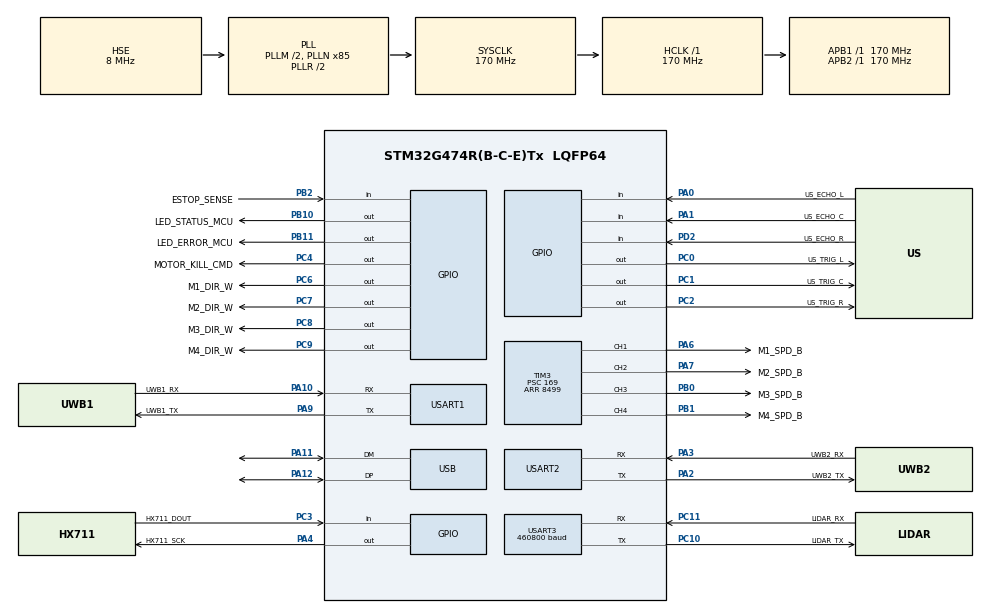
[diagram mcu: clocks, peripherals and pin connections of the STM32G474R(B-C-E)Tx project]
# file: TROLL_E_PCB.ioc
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Dma.Request0=USART3_RX
Dma.Request1=USART1_RX
Dma.Request2=USART2_RX
Dma.USART1_RX.1.Direction=DMA_PERIPH_TO_MEMORY
Dma.USART1_RX.1.EventEnable=DISABLE
Dma.USART1_RX.1.Instance=DMA1_Channel2
Dma.USART1_RX.1.MemDataAlignment=DMA_MDATAALIGN_BYTE
Dma.USART1_RX.1.MemInc=DMA_MINC_ENABLE
Dma.USART1_RX.1.Mode=DMA_CIRCULAR
Dma.USART1_RX.1.PeriphDataAlignment=DMA_PDATAALIGN_BYTE
Dma.USART1_RX.1.PeriphInc=DMA_PINC_DISABLE
Dma.USART1_RX.1.Polarity=HAL_DMAMUX_REQ_GEN_RISING
Dma.USART1_RX.1.Priority=DMA_PRIORITY_LOW
Dma.USART1_RX.1.RequestNumber=1
Dma.USART1_RX.1.SignalID=NONE
Dma.USART1_RX.1.SyncEnable=DISABLE
Dma.USART1_RX.1.SyncPolarity=HAL_DMAMUX_SYNC_NO_EVENT
Dma.USART1_RX.1.SyncRequestNumber=1
Dma.USART1_RX.1.SyncSignalID=NONE
Dma.USART2_RX.2.Direction=DMA_PERIPH_TO_MEMORY
Dma.USART2_RX.2.EventEnable=DISABLE
Dma.USART2_RX.2.Instance=DMA1_Channel3
Dma.USART2_RX.2.MemDataAlignment=DMA_MDATAALIGN_BYTE
Dma.USART2_RX.2.MemInc=DMA_MINC_ENABLE
Dma.USART2_RX.2.Mode=DMA_CIRCULAR
Dma.USART2_RX.2.PeriphDataAlignment=DMA_PDATAALIGN_BYTE
Dma.USART2_RX.2.PeriphInc=DMA_PINC_DISABLE
Dma.USART2_RX.2.Polarity=HAL_DMAMUX_REQ_GEN_RISING
Dma.USART2_RX.2.Priority=DMA_PRIORITY_LOW
Dma.USART2_RX.2.RequestNumber=1
Dma.USART2_RX.2.SignalID=NONE
Dma.USART2_RX.2.SyncEnable=DISABLE
Dma.USART2_RX.2.SyncPolarity=HAL_DMAMUX_SYNC_NO_EVENT
Dma.USART2_RX.2.SyncRequestNumber=1
Dma.USART2_RX.2.SyncSignalID=NONE
Dma.USART3_RX.0.Direction=DMA_PERIPH_TO_MEMORY
Dma.USART3_RX.0.EventEnable=DISABLE
Dma.USART3_RX.0.Instance=DMA1_Channel1
Dma.USART3_RX.0.MemDataAlignment=DMA_MDATAALIGN_BYTE
Dma.USART3_RX.0.MemInc=DMA_MINC_ENABLE
Dma.USART3_RX.0.Mode=DMA_CIRCULAR
Dma.USART3_RX.0.PeriphDataAlignment=DMA_PDATAALIGN_BYTE
Dma.USART3_RX.0.PeriphInc=DMA_PINC_DISABLE
Dma.USART3_RX.0.Polarity=HAL_DMAMUX_REQ_GEN_RISING
Dma.USART3_RX.0.Priority=DMA_PRIORITY_LOW
Dma.USART3_RX.0.RequestNumber=1
Dma.USART3_RX.0.SignalID=NONE
Dma.USART3_RX.0.SyncEnable=DISABLE
Dma.USART3_RX.0.SyncPolarity=HAL_DMAMUX_SYNC_NO_EVENT
Dma.USART3_RX.0.SyncRequestNumber=1
Dma.USART3_RX.0.SyncSignalID=NONE
Mcu.Family=STM32G4
Mcu.Name=STM32G474R(B-C-E)Tx
Mcu.Package=LQFP64
NVIC.DMA1_Channel1_IRQn=true\:0\:0\:false\:false\:true\:false\:true\:true
NVIC.DMA1_Channel2_IRQn=true\:0\:0\:false\:false\:true\:false\:true\:true
NVIC.DMA1_Channel3_IRQn=true\:0\:0\:false\:false\:true\:false\:true\:true
NVIC.PriorityGroup=NVIC_PRIORITYGROUP_4
NVIC.USART1_IRQn=true\:0\:0\:false\:false\:true\:true\:true\:true
NVIC.USART2_IRQn=true\:0\:0\:false\:false\:true\:true\:true\:true
NVIC.USART3_IRQn=true\:0\:0\:false\:false\:true\:true\:true\:true
NVIC.USB_LP_IRQn=true\:0\:0\:false\:false\:true\:false\:true\:true
PA0.GPIO_Label=US_ECHO_L
PA0.Signal=GPIO_Input
PA1.GPIO_Label=US_ECHO_C
PA1.Signal=GPIO_Input
PA10.GPIO_Label=UWB1_RX
PA10.Mode=Asynchronous
PA10.Signal=USART1_RX
PA11.Mode=Device
PA11.Signal=USB_DM
PA12.Mode=Device
PA12.Signal=USB_DP
PA13.Mode=Serial_Wire
PA13.Signal=SYS_JTMS-SWDIO
PA14.Mode=Serial_Wire
PA14.Signal=SYS_JTCK-SWCLK
PA2.GPIO_Label=UWB2_TX
PA2.Mode=Asynchronous
PA2.Signal=USART2_TX
PA3.GPIO_Label=UWB2_RX
PA3.Mode=Asynchronous
PA3.Signal=USART2_RX
PA4.GPIO_Label=HX711_SCK
PA4.GPIO_PuPd=GPIO_NOPULL
PA4.Signal=GPIO_Output
PA6.GPIO_Label=M1_SPD_B
PA6.Signal=S_TIM3_CH1
PA7.GPIO_Label=M2_SPD_B
PA7.Signal=S_TIM3_CH2
PA9.GPIO_Label=UWB1_TX
PA9.Mode=Asynchronous
PA9.Signal=USART1_TX
PB0.GPIO_Label=M3_SPD_B
PB0.Signal=S_TIM3_CH3
PB1.GPIO_Label=M4_SPD_B
PB1.Signal=S_TIM3_CH4
PB10.GPIO_Label=LED_STATUS_MCU
PB10.Signal=GPIO_Output
PB11.GPIO_Label=LED_ERROR_MCU
PB11.Signal=GPIO_Output
PB2.GPIO_Label=ESTOP_SENSE
PB2.Signal=GPIO_Input
PC0.GPIO_Label=US_TRIG_L
PC0.Signal=GPIO_Output
PC1.GPIO_Label=US_TRIG_C
PC1.Signal=GPIO_Output
PC10.GPIO_Label=LiDAR_TX
PC10.Mode=Asynchronous
PC10.Signal=USART3_TX
PC11.GPIO_Label=LiDAR_RX
PC11.Mode=Asynchronous
PC11.Signal=USART3_RX
PC2.GPIO_Label=US_TRIG_R
PC2.Signal=GPIO_Output
PC3.GPIO_Label=HX711_DOUT
PC3.GPIO_PuPd=GPIO_PULLUP
PC3.Signal=GPIO_Input
PC4.GPIO_Label=MOTOR_KILL_CMD
PC4.PinState=GPIO_PIN_SET
PC4.Signal=GPIO_Output
PC6.GPIO_Label=M1_DIR_W
PC6.Signal=GPIO_Output
PC7.GPIO_Label=M2_DIR_W
PC7.Signal=GPIO_Output
PC8.GPIO_Label=M3_DIR_W
PC8.Signal=GPIO_Output
PC9.GPIO_Label=M4_DIR_W
PC9.Signal=GPIO_Output
PD2.GPIO_Label=US_ECHO_R
PD2.Signal=GPIO_Input
PF0-OSC_IN.Mode=HSE-External-Oscillator
PF0-OSC_IN.Signal=RCC_OSC_IN
PF1-OSC_OUT.Mode=HSE-External-Oscillator
PF1-OSC_OUT.Signal=RCC_OSC_OUT
ProjectManager.HeapSize=0x1000
ProjectManager.StackSize=0x400
ProjectManager.TargetToolchain=STM32CubeIDE
RCC.ADC12Freq_Value=170000000
RCC.ADC345Freq_Value=170000000
RCC.AHBFreq_Value=170000000
RCC.APB1Freq_Value=170000000
RCC.APB1TimFreq_Value=170000000
RCC.APB2Freq_Value=170000000
RCC.APB2TimFreq_Value=170000000
RCC.CK48CLockSelection=RCC_USBCLKSOURCE_HSI48
RCC.CortexFreq_Value=170000000
RCC.EXTERNAL_CLOCK_VALUE=12288000
RCC.HCLKFreq_Value=170000000
RCC.HSE_VALUE=8000000
RCC.HSI48_VALUE=48000000
RCC.HSI_VALUE=16000000
RCC.LSE_VALUE=32768
RCC.PLLM=RCC_PLLM_DIV2
RCC.PLLN=85
RCC.PLLQ=RCC_PLLQ_DIV4
RCC.PLLSourceVirtual=RCC_PLLSOURCE_HSE
RCC.SYSCLKFreq_VALUE=170000000
RCC.SYSCLKSource=RCC_SYSCLKSOURCE_PLLCLK
RCC.USBFreq_Value=48000000
RCC.VCOOutputFreq_Value=340000000
SH.S_TIM3_CH1.0=TIM3_CH1,PWM Generation1 CH1
SH.S_TIM3_CH2.0=TIM3_CH2,PWM Generation2 CH2
SH.S_TIM3_CH3.0=TIM3_CH3,PWM Generation3 CH3
SH.S_TIM3_CH4.0=TIM3_CH4,PWM Generation4 CH4
TIM2.Prescaler=169
TIM3.AutoReloadPreload=TIM_AUTORELOAD_PRELOAD_ENABLE
TIM3.Channel-PWM\ Generation1\ CH1=TIM_CHANNEL_1
TIM3.Channel-PWM\ Generation2\ CH2=TIM_CHANNEL_2
TIM3.Channel-PWM\ Generation3\ CH3=TIM_CHANNEL_3
TIM3.Channel-PWM\ Generation4\ CH4=TIM_CHANNEL_4
TIM3.PeriodNoDither=8499
TIM3.Prescaler=169
TIM3.PulseNoDither_1=0
TIM3.PulseNoDither_2=0
TIM3.PulseNoDither_3=0
TIM3.PulseNoDither_4=0
USART1.VirtualMode-Asynchronous=VM_ASYNC
USART2.VirtualMode-Asynchronous=VM_ASYNC
USART3.BaudRate=460800
USART3.VirtualMode-Asynchronous=VM_ASYNC
USB_DEVICE.CLASS_NAME_FS=CDC
USB_DEVICE.VirtualMode=Cdc
USB_DEVICE.VirtualModeFS=Cdc_FS
VP_RCC_VS_USB.Mode=USB_FS
VP_SYS_VS_DBSignals.Mode=DisableDeadBatterySignals
VP_TIM2_VS_ClockSourceINT.Mode=Internal
VP_TIM3_VS_ClockSourceINT.Mode=Internal
VP_USB_DEVICE_VS_USB_DEVICE_CDC_FS.Mode=CDC_FS
board=custom

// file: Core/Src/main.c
/* USER CODE BEGIN Header */
/**
  ******************************************************************************
  * @file           : main.c
  * @brief          : Main program body
  ******************************************************************************
  * @attention
  *
  * Copyright (c) 2026 STMicroelectronics.
  * All rights reserved.
  *
  * This software is licensed under terms that can be found in the LICENSE file
  * in the root directory of this software component.
  * If no LICENSE file comes with this software, it is provided AS-IS.
  *
  ******************************************************************************
  */
/* USER CODE END Header */
#include "main.h"
#include "usb_device.h"

/* USER CODE BEGIN Includes */
#include "troll_e.h"
/* USER CODE END Includes */

TIM_HandleTypeDef htim2;
TIM_HandleTypeDef htim3;

UART_HandleTypeDef huart1;
UART_HandleTypeDef huart2;
UART_HandleTypeDef huart3;
DMA_HandleTypeDef hdma_usart1_rx;
DMA_HandleTypeDef hdma_usart2_rx;
DMA_HandleTypeDef hdma_usart3_rx;

void SystemClock_Config(void);
static void MX_GPIO_Init(void);
static void MX_DMA_Init(void);
static void MX_TIM2_Init(void);
static void MX_TIM3_Init(void);
static void MX_USART3_UART_Init(void);
static void MX_USART1_UART_Init(void);
static void MX_USART2_UART_Init(void);

int main(void)
{

  /* MCU Configuration--------------------------------------------------------*/

  /* Reset of all peripherals, Initializes the Flash interface and the Systick. */
  HAL_Init();

  /* Configure the system clock */
  SystemClock_Config();

  /* Initialize all configured peripherals */
  MX_GPIO_Init();
  MX_DMA_Init();
  MX_TIM2_Init();
  MX_TIM3_Init();
  MX_USART3_UART_Init();
  MX_USART1_UART_Init();
  MX_USART2_UART_Init();
  MX_USB_Device_Init();
  /* USER CODE BEGIN 2 */
  TrollE_Init();
  /* USER CODE END 2 */

  /* Infinite loop */
  while (1)
  {

    /* USER CODE BEGIN 3 */
	  TrollE_Loop();
  }
  /* USER CODE END 3 */
}

void SystemClock_Config(void)
{
  RCC_OscInitTypeDef RCC_OscInitStruct = {0};
  RCC_ClkInitTypeDef RCC_ClkInitStruct = {0};
  RCC_CRSInitTypeDef pInit = {0};

  /** Configure the main internal regulator output voltage
  */
  HAL_PWREx_ControlVoltageScaling(PWR_REGULATOR_VOLTAGE_SCALE1_BOOST);

  /** Initializes the RCC Oscillators according to the specified parameters
  * in the RCC_OscInitTypeDef structure.
  */
  RCC_OscInitStruct.OscillatorType = RCC_OSCILLATORTYPE_HSI48|RCC_OSCILLATORTYPE_HSE;
  RCC_OscInitStruct.HSEState = RCC_HSE_ON;
  RCC_OscInitStruct.HSI48State = RCC_HSI48_ON;
  RCC_OscInitStruct.PLL.PLLState = RCC_PLL_ON;
  RCC_OscInitStruct.PLL.PLLSource = RCC_PLLSOURCE_HSE;
  RCC_OscInitStruct.PLL.PLLM = RCC_PLLM_DIV2;
  RCC_OscInitStruct.PLL.PLLN = 85;
  RCC_OscInitStruct.PLL.PLLP = RCC_PLLP_DIV2;
  RCC_OscInitStruct.PLL.PLLQ = RCC_PLLQ_DIV4;
  RCC_OscInitStruct.PLL.PLLR = RCC_PLLR_DIV2;
  if (HAL_RCC_OscConfig(&RCC_OscInitStruct) != HAL_OK)
  {
    Error_Handler();
  }

  /** Initializes the CPU, AHB and APB buses clocks
  */
  RCC_ClkInitStruct.ClockType = RCC_CLOCKTYPE_HCLK|RCC_CLOCKTYPE_SYSCLK
                              |RCC_CLOCKTYPE_PCLK1|RCC_CLOCKTYPE_PCLK2;
  RCC_ClkInitStruct.SYSCLKSource = RCC_SYSCLKSOURCE_PLLCLK;
  RCC_ClkInitStruct.AHBCLKDivider = RCC_SYSCLK_DIV1;
  RCC_ClkInitStruct.APB1CLKDivider = RCC_HCLK_DIV1;
  RCC_ClkInitStruct.APB2CLKDivider = RCC_HCLK_DIV1;

  if (HAL_RCC_ClockConfig(&RCC_ClkInitStruct, FLASH_LATENCY_4) != HAL_OK)
  {
    Error_Handler();
  }

  /** Enable the SYSCFG APB clock
  */
  __HAL_RCC_CRS_CLK_ENABLE();

  /** Configures CRS
  */
  pInit.Prescaler = RCC_CRS_SYNC_DIV1;
  pInit.Source = RCC_CRS_SYNC_SOURCE_USB;
  pInit.Polarity = RCC_CRS_SYNC_POLARITY_RISING;
  pInit.ReloadValue = __HAL_RCC_CRS_RELOADVALUE_CALCULATE(48000000,1000);
  pInit.ErrorLimitValue = 34;
  pInit.HSI48CalibrationValue = 32;

  HAL_RCCEx_CRSConfig(&pInit);
}

static void MX_TIM2_Init(void)
{

  TIM_ClockConfigTypeDef sClockSourceConfig = {0};
  TIM_MasterConfigTypeDef sMasterConfig = {0};

  htim2.Instance = TIM2;
  htim2.Init.Prescaler = 169;
  htim2.Init.CounterMode = TIM_COUNTERMODE_UP;
  htim2.Init.Period = 4294967295;
  htim2.Init.ClockDivision = TIM_CLOCKDIVISION_DIV1;
  htim2.Init.AutoReloadPreload = TIM_AUTORELOAD_PRELOAD_DISABLE;
  if (HAL_TIM_Base_Init(&htim2) != HAL_OK)
  {
    Error_Handler();
  }
  sClockSourceConfig.ClockSource = TIM_CLOCKSOURCE_INTERNAL;
  if (HAL_TIM_ConfigClockSource(&htim2, &sClockSourceConfig) != HAL_OK)
  {
    Error_Handler();
  }
  sMasterConfig.MasterOutputTrigger = TIM_TRGO_RESET;
  sMasterConfig.MasterSlaveMode = TIM_MASTERSLAVEMODE_DISABLE;
  if (HAL_TIMEx_MasterConfigSynchronization(&htim2, &sMasterConfig) != HAL_OK)
  {
    Error_Handler();
  }

}

static void MX_TIM3_Init(void)
{

  TIM_ClockConfigTypeDef sClockSourceConfig = {0};
  TIM_MasterConfigTypeDef sMasterConfig = {0};
  TIM_OC_InitTypeDef sConfigOC = {0};

  htim3.Instance = TIM3;
  htim3.Init.Prescaler = 169;
  htim3.Init.CounterMode = TIM_COUNTERMODE_UP;
  htim3.Init.Period = 8499;
  htim3.Init.ClockDivision = TIM_CLOCKDIVISION_DIV1;
  htim3.Init.AutoReloadPreload = TIM_AUTORELOAD_PRELOAD_ENABLE;
  if (HAL_TIM_Base_Init(&htim3) != HAL_OK)
  {
    Error_Handler();
  }
  sClockSourceConfig.ClockSource = TIM_CLOCKSOURCE_INTERNAL;
  if (HAL_TIM_ConfigClockSource(&htim3, &sClockSourceConfig) != HAL_OK)
  {
    Error_Handler();
  }
  if (HAL_TIM_PWM_Init(&htim3) != HAL_OK)
  {
    Error_Handler();
  }
  sMasterConfig.MasterOutputTrigger = TIM_TRGO_RESET;
  sMasterConfig.MasterSlaveMode = TIM_MASTERSLAVEMODE_DISABLE;
  if (HAL_TIMEx_MasterConfigSynchronization(&htim3, &sMasterConfig) != HAL_OK)
  {
    Error_Handler();
  }
  sConfigOC.OCMode = TIM_OCMODE_PWM1;
  sConfigOC.Pulse = 0;
  sConfigOC.OCPolarity = TIM_OCPOLARITY_HIGH;
  sConfigOC.OCFastMode = TIM_OCFAST_DISABLE;
  if (HAL_TIM_PWM_ConfigChannel(&htim3, &sConfigOC, TIM_CHANNEL_1) != HAL_OK)
  {
    Error_Handler();
  }
  if (HAL_TIM_PWM_ConfigChannel(&htim3, &sConfigOC, TIM_CHANNEL_2) != HAL_OK)
  {
    Error_Handler();
  }
  if (HAL_TIM_PWM_ConfigChannel(&htim3, &sConfigOC, TIM_CHANNEL_3) != HAL_OK)
  {
    Error_Handler();
  }
  if (HAL_TIM_PWM_ConfigChannel(&htim3, &sConfigOC, TIM_CHANNEL_4) != HAL_OK)
  {
    Error_Handler();
  }
  HAL_TIM_MspPostInit(&htim3);

}

static void MX_USART1_UART_Init(void)
{

  huart1.Instance = USART1;
  huart1.Init.BaudRate = 115200;
  huart1.Init.WordLength = UART_WORDLENGTH_8B;
  huart1.Init.StopBits = UART_STOPBITS_1;
  huart1.Init.Parity = UART_PARITY_NONE;
  huart1.Init.Mode = UART_MODE_TX_RX;
  huart1.Init.HwFlowCtl = UART_HWCONTROL_NONE;
  huart1.Init.OverSampling = UART_OVERSAMPLING_16;
  huart1.Init.OneBitSampling = UART_ONE_BIT_SAMPLE_DISABLE;
  huart1.Init.ClockPrescaler = UART_PRESCALER_DIV1;
  huart1.AdvancedInit.AdvFeatureInit = UART_ADVFEATURE_NO_INIT;
  if (HAL_UART_Init(&huart1) != HAL_OK)
  {
    Error_Handler();
  }
  if (HAL_UARTEx_SetTxFifoThreshold(&huart1, UART_TXFIFO_THRESHOLD_1_8) != HAL_OK)
  {
    Error_Handler();
  }
  if (HAL_UARTEx_SetRxFifoThreshold(&huart1, UART_RXFIFO_THRESHOLD_1_8) != HAL_OK)
  {
    Error_Handler();
  }
  if (HAL_UARTEx_DisableFifoMode(&huart1) != HAL_OK)
  {
    Error_Handler();
  }

}

static void MX_USART2_UART_Init(void)
{

  huart2.Instance = USART2;
  huart2.Init.BaudRate = 115200;
  huart2.Init.WordLength = UART_WORDLENGTH_8B;
  huart2.Init.StopBits = UART_STOPBITS_1;
  huart2.Init.Parity = UART_PARITY_NONE;
  huart2.Init.Mode = UART_MODE_TX_RX;
  huart2.Init.HwFlowCtl = UART_HWCONTROL_NONE;
  huart2.Init.OverSampling = UART_OVERSAMPLING_16;
  huart2.Init.OneBitSampling = UART_ONE_BIT_SAMPLE_DISABLE;
  huart2.Init.ClockPrescaler = UART_PRESCALER_DIV1;
  huart2.AdvancedInit.AdvFeatureInit = UART_ADVFEATURE_NO_INIT;
  if (HAL_UART_Init(&huart2) != HAL_OK)
  {
    Error_Handler();
  }
  if (HAL_UARTEx_SetTxFifoThreshold(&huart2, UART_TXFIFO_THRESHOLD_1_8) != HAL_OK)
  {
    Error_Handler();
  }
  if (HAL_UARTEx_SetRxFifoThreshold(&huart2, UART_RXFIFO_THRESHOLD_1_8) != HAL_OK)
  {
    Error_Handler();
  }
  if (HAL_UARTEx_DisableFifoMode(&huart2) != HAL_OK)
  {
    Error_Handler();
  }

}

static void MX_USART3_UART_Init(void)
{

  huart3.Instance = USART3;
  huart3.Init.BaudRate = 460800;
  huart3.Init.WordLength = UART_WORDLENGTH_8B;
  huart3.Init.StopBits = UART_STOPBITS_1;
  huart3.Init.Parity = UART_PARITY_NONE;
  huart3.Init.Mode = UART_MODE_TX_RX;
  huart3.Init.HwFlowCtl = UART_HWCONTROL_NONE;
  huart3.Init.OverSampling = UART_OVERSAMPLING_16;
  huart3.Init.OneBitSampling = UART_ONE_BIT_SAMPLE_DISABLE;
  huart3.Init.ClockPrescaler = UART_PRESCALER_DIV1;
  huart3.AdvancedInit.AdvFeatureInit = UART_ADVFEATURE_NO_INIT;
  if (HAL_UART_Init(&huart3) != HAL_OK)
  {
    Error_Handler();
  }
  if (HAL_UARTEx_SetTxFifoThreshold(&huart3, UART_TXFIFO_THRESHOLD_1_8) != HAL_OK)
  {
    Error_Handler();
  }
  if (HAL_UARTEx_SetRxFifoThreshold(&huart3, UART_RXFIFO_THRESHOLD_1_8) != HAL_OK)
  {
    Error_Handler();
  }
  if (HAL_UARTEx_DisableFifoMode(&huart3) != HAL_OK)
  {
    Error_Handler();
  }

}

static void MX_DMA_Init(void)
{

  /* DMA controller clock enable */
  __HAL_RCC_DMAMUX1_CLK_ENABLE();
  __HAL_RCC_DMA1_CLK_ENABLE();

  /* DMA interrupt init */
  /* DMA1_Channel1_IRQn interrupt configuration */
  HAL_NVIC_SetPriority(DMA1_Channel1_IRQn, 0, 0);
  HAL_NVIC_EnableIRQ(DMA1_Channel1_IRQn);
  /* DMA1_Channel2_IRQn interrupt configuration */
  HAL_NVIC_SetPriority(DMA1_Channel2_IRQn, 0, 0);
  HAL_NVIC_EnableIRQ(DMA1_Channel2_IRQn);
  /* DMA1_Channel3_IRQn interrupt configuration */
  HAL_NVIC_SetPriority(DMA1_Channel3_IRQn, 0, 0);
  HAL_NVIC_EnableIRQ(DMA1_Channel3_IRQn);

}

static void MX_GPIO_Init(void)
{
  GPIO_InitTypeDef GPIO_InitStruct = {0};

  /* GPIO Ports Clock Enable */
  __HAL_RCC_GPIOF_CLK_ENABLE();
  __HAL_RCC_GPIOC_CLK_ENABLE();
  __HAL_RCC_GPIOA_CLK_ENABLE();
  __HAL_RCC_GPIOB_CLK_ENABLE();
  __HAL_RCC_GPIOD_CLK_ENABLE();

  /*Configure GPIO pin Output Level */
  HAL_GPIO_WritePin(GPIOC, US_TRIG_L_Pin|US_TRIG_C_Pin|US_TRIG_R_Pin|M1_DIR_W_Pin
                          |M2_DIR_W_Pin|M3_DIR_W_Pin|M4_DIR_W_Pin, GPIO_PIN_RESET);

  /*Configure GPIO pin Output Level */
  HAL_GPIO_WritePin(HX711_SCK_GPIO_Port, HX711_SCK_Pin, GPIO_PIN_RESET);

  /*Configure GPIO pin Output Level */
  HAL_GPIO_WritePin(MOTOR_KILL_CMD_GPIO_Port, MOTOR_KILL_CMD_Pin, GPIO_PIN_SET);

  /*Configure GPIO pin Output Level */
  HAL_GPIO_WritePin(GPIOB, LED_STATUS_MCU_Pin|LED_ERROR_MCU_Pin, GPIO_PIN_RESET);

  /*Configure GPIO pins : US_TRIG_L_Pin US_TRIG_C_Pin US_TRIG_R_Pin MOTOR_KILL_CMD_Pin
                           M1_DIR_W_Pin M2_DIR_W_Pin M3_DIR_W_Pin M4_DIR_W_Pin */
  GPIO_InitStruct.Pin = US_TRIG_L_Pin|US_TRIG_C_Pin|US_TRIG_R_Pin|MOTOR_KILL_CMD_Pin
                          |M1_DIR_W_Pin|M2_DIR_W_Pin|M3_DIR_W_Pin|M4_DIR_W_Pin;
  GPIO_InitStruct.Mode = GPIO_MODE_OUTPUT_PP;
  GPIO_InitStruct.Pull = GPIO_NOPULL;
  GPIO_InitStruct.Speed = GPIO_SPEED_FREQ_LOW;
  HAL_GPIO_Init(GPIOC, &GPIO_InitStruct);

  /*Configure GPIO pin : HX711_DOUT_Pin */
  GPIO_InitStruct.Pin = HX711_DOUT_Pin;
  GPIO_InitStruct.Mode = GPIO_MODE_INPUT;
  GPIO_InitStruct.Pull = GPIO_PULLUP;
  HAL_GPIO_Init(HX711_DOUT_GPIO_Port, &GPIO_InitStruct);

  /*Configure GPIO pins : US_ECHO_L_Pin US_ECHO_C_Pin */
  GPIO_InitStruct.Pin = US_ECHO_L_Pin|US_ECHO_C_Pin;
  GPIO_InitStruct.Mode = GPIO_MODE_INPUT;
  GPIO_InitStruct.Pull = GPIO_NOPULL;
  HAL_GPIO_Init(GPIOA, &GPIO_InitStruct);

  /*Configure GPIO pin : HX711_SCK_Pin */
  GPIO_InitStruct.Pin = HX711_SCK_Pin;
  GPIO_InitStruct.Mode = GPIO_MODE_OUTPUT_PP;
  GPIO_InitStruct.Pull = GPIO_NOPULL;
  GPIO_InitStruct.Speed = GPIO_SPEED_FREQ_LOW;
  HAL_GPIO_Init(HX711_SCK_GPIO_Port, &GPIO_InitStruct);

  /*Configure GPIO pin : ESTOP_SENSE_Pin */
  GPIO_InitStruct.Pin = ESTOP_SENSE_Pin;
  GPIO_InitStruct.Mode = GPIO_MODE_INPUT;
  GPIO_InitStruct.Pull = GPIO_NOPULL;
  HAL_GPIO_Init(ESTOP_SENSE_GPIO_Port, &GPIO_InitStruct);

  /*Configure GPIO pins : LED_STATUS_MCU_Pin LED_ERROR_MCU_Pin */
  GPIO_InitStruct.Pin = LED_STATUS_MCU_Pin|LED_ERROR_MCU_Pin;
  GPIO_InitStruct.Mode = GPIO_MODE_OUTPUT_PP;
  GPIO_InitStruct.Pull = GPIO_NOPULL;
  GPIO_InitStruct.Speed = GPIO_SPEED_FREQ_LOW;
  HAL_GPIO_Init(GPIOB, &GPIO_InitStruct);

  /*Configure GPIO pin : US_ECHO_R_Pin */
  GPIO_InitStruct.Pin = US_ECHO_R_Pin;
  GPIO_InitStruct.Mode = GPIO_MODE_INPUT;
  GPIO_InitStruct.Pull = GPIO_NOPULL;
  HAL_GPIO_Init(US_ECHO_R_GPIO_Port, &GPIO_InitStruct);

}

void Error_Handler(void)
{
  __disable_irq();
  while (1)
  {
  }
}
